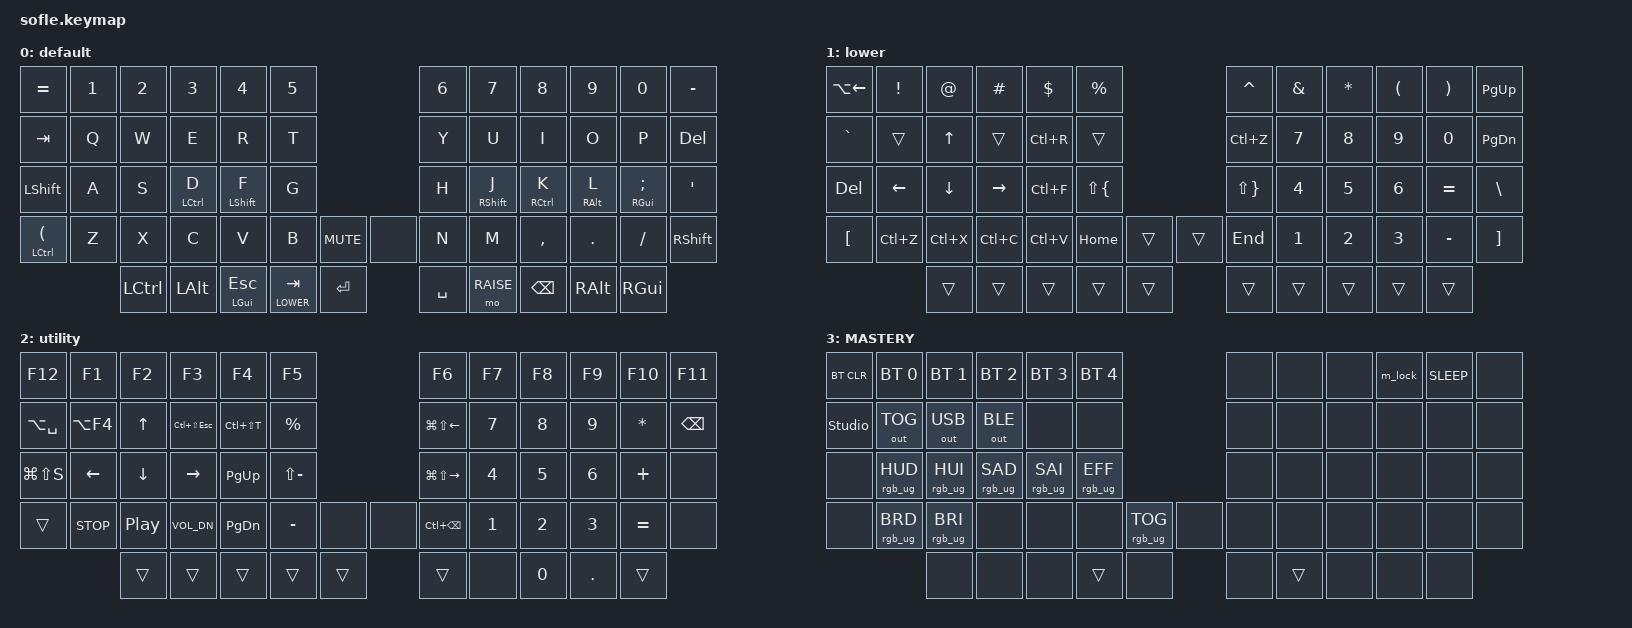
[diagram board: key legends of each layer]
/*
 * Copyright (c) 2020 The ZMK Contributors
 *
 * SPDX-License-Identifier: MIT
 */

#include <behaviors.dtsi>
#include <dt-bindings/zmk/keys.h>
#include <dt-bindings/zmk/bt.h>
#include <dt-bindings/zmk/rgb.h>
#include <dt-bindings/zmk/ext_power.h>
#include <dt-bindings/zmk/outputs.h>

#define BASE 0
#define LOWER 1
#define RAISE 2
#define ADJUST 3

/ {
    // Activate ADJUST layer by pressing raise and lower
    conditional_layers {
        compatible = "zmk,conditional-layers";
        adjust_layer {
            if-layers = <LOWER RAISE>;
            then-layer = <ADJUST>;
        };
    };

    behaviors {
        hm: homerow_mods {
            compatible = "zmk,behavior-hold-tap";
            label = "HOMEROW_MODS";
            #binding-cells = <2>;
            tapping-term-ms = <200>;
            quick-tap-ms = <175>;
            require-prior-idle-ms = <150>;
            flavor = "balanced";
            bindings = <&kp>, <&kp>;
        };
    };

    macros {
        // Universal Lock Screen (Locks both Windows via Win+L and macOS via Ctrl+Cmd+Q)
        m_lock: m_lock {
            compatible = "zmk,behavior-macro";
            #binding-cells = <0>;
            bindings = <&kp LG(L) &kp LG(LC(Q))>;
        };
    };

    keymap {
        compatible = "zmk,keymap";

        default_layer {
            display-name = "default";
            bindings = <
&kp EQUAL &kp N1 &kp N2   &kp N3   &kp N4    &kp N5                           &kp N6 &kp N7    &kp N8    &kp N9   &kp N0   &kp MINUS
&kp TAB   &kp Q  &kp W    &kp E    &kp R     &kp T                            &kp Y  &kp U     &kp I     &kp O    &kp P    &kp DEL
&kp LSHFT &kp A  &kp S    &hm LCTRL D &hm LSHFT F &kp G                       &kp H  &hm RSHFT J &hm RCTRL K &hm RALT L &hm RGUI SEMI &kp SQT
&hm LCTRL LPAR &kp Z  &kp X    &kp C    &kp V     &kp B      &kp C_MUTE &none      &kp N  &kp M     &kp COMMA &kp DOT  &kp FSLH &kp RSHFT
                 &kp LCTRL &kp LALT &mt LGUI ESC &lt LOWER TAB  &kp RET    &kp SPACE  &mo RAISE  &kp BSPC &kp RALT  &kp RGUI
            >;

            sensor-bindings = <&inc_dec_kp C_VOL_UP C_VOL_DN &inc_dec_kp PG_UP PG_DN>;
        };

        lower_layer {
            display-name = "lower";
            bindings = <
&kp LA(LEFT)  &kp EXCL  &kp AT    &kp HASH  &kp DLLR      &kp PRCNT                 &kp CARET &kp AMPS  &kp ASTRK &kp LPAR  &kp RPAR  &kp PG_UP
&kp GRAVE     &trans    &kp UP    &trans    &kp LC(R)     &trans                    &kp LC(Z) &kp N7    &kp N8    &kp N9    &kp N0    &kp PG_DN
&kp DEL       &kp LEFT  &kp DOWN  &kp RIGHT &kp LC(F)     &kp LS(LBRC)              &kp LS(RBRC) &kp N4  &kp N5    &kp N6    &kp EQUAL &kp BSLH
&kp LBKT      &kp LC(Z) &kp LC(X) &kp LC(C) &kp LC(V)     &kp HOME &trans &trans    &kp END   &kp N1    &kp N2    &kp N3    &kp MINUS &kp RBKT
                        &trans    &trans    &trans        &trans        &trans &trans &trans   &trans    &trans    &trans
            >;

            sensor-bindings = <&inc_dec_kp C_VOL_UP C_VOL_DN &inc_dec_kp PG_UP PG_DN>;
        };

        raise_layer {
            display-name = "utility";
// ------------------------------------------------------------------------------------------------------------
// |  F12  |  F1   |  F2  |  F3   |  F4   |  F5  |                   |  F6   |  F7   |  F8   |  F9  |  F10  |  F11  |
// | RAYCST| ALT+F4|  UP  | TSKMGR| REOPN |   %  |                   | MON_L |  7    |  8    |  9   |   *   | BKSP  |
// | SNIP  |  LEFT | DOWN | RIGHT | PGUP  |   _  |                   | MON_R |  4    |  5    |  6   |   +   |       |
// |       |  MSTP | MPLY | VOLD  | PGDN  |   -  |      |  |         | C+BSPC|  1    |  2    |  3   |   =   |       |
//                 |      |       |       |      |      |  |         |       |  0    |  .    |      |
            bindings = <
&kp F12        &kp F1     &kp F2    &kp F3         &kp F4        &kp F5                        &kp F6          &kp F7    &kp F8    &kp F9    &kp F10   &kp F11
&kp LA(SPACE)  &kp LA(F4) &kp UP    &kp LC(LS(ESC))&kp LC(LS(T)) &kp PRCNT                     &kp LG(LS(LEFT))&kp N7    &kp N8    &kp N9    &kp ASTRK &kp BSPC
&kp LG(LS(S))  &kp LEFT   &kp DOWN  &kp RIGHT      &kp PG_UP     &kp LS(MINUS)                 &kp LG(LS(RIGHT))&kp N4   &kp N5    &kp N6    &kp PLUS  &none
&trans         &kp C_STOP &kp C_PP  &kp C_VOL_DN   &kp PG_DN     &kp MINUS  &none &none        &kp LC(BSPC)    &kp N1    &kp N2    &kp N3    &kp EQUAL &none
                          &trans    &trans         &trans        &trans     &trans       &trans &none          &kp N0    &kp DOT   &trans
            >;

            // Left Encoder: Volume | Right Encoder: Switch Windows Virtual Desktops (Ctrl + Win + Right/Left)
            sensor-bindings = <&inc_dec_kp C_VOL_UP C_VOL_DN &inc_dec_kp LC(LG(RIGHT)) LC(LG(LEFT))>;
        };

        adjust_layer {
            display-name = "MASTERY";
// ----------------------------------------------------------------------------------------------------------------------------
// | BTCLR  |  BT1    |  BT2    |   BT3   |   BT4   |   BT5   |                  |      |      |       | LOCK | SLEEP |       |
// | UNLOCK | OUT_TOG | OUT_USB | OUT_BLE |         |         |                  |      |      |       |      |       |       |
// |        | RGB_HUD | RGB_HUI | RGB_SAD | RGB_SAI | RGB_EFF |                  |      |      |       |      |       |       |
// |        | RGB_BRD | RGB_BRI |         |         |         | RGB_TOG | |      |      |      |       |      |       |       |
//                    |         |         |         |         |         | |      |      |      |       |      |
            bindings = <
&bt BT_CLR        &bt BT_SEL 0    &bt BT_SEL 1    &bt BT_SEL 2    &bt BT_SEL 3    &bt BT_SEL 4                            &none &none &none &m_lock     &kp C_SLEEP &none
&studio_unlock    &out OUT_TOG    &out OUT_USB    &out OUT_BLE    &none           &none                                   &none &none &none &none       &none       &none
&none             &rgb_ug RGB_HUD &rgb_ug RGB_HUI &rgb_ug RGB_SAD &rgb_ug RGB_SAI &rgb_ug RGB_EFF                         &none &none &none &none       &none       &none
&none             &rgb_ug RGB_BRD &rgb_ug RGB_BRI &none           &none           &none            &rgb_ug RGB_TOG &none  &none &none &none &none       &none       &none
                                  &none           &none           &none           &trans           &none           &none  &trans &none &none &none
            >;
            
            // Left Encoder = Ghostty Split Navigation (Cmd+Alt+Arrows) | Right Encoder = Neovim Jumps
            sensor-bindings = <&inc_dec_kp LA(LG(RIGHT)) LA(LG(LEFT)) &inc_dec_kp LC(O) LC(I)>;
        };
    };
};
